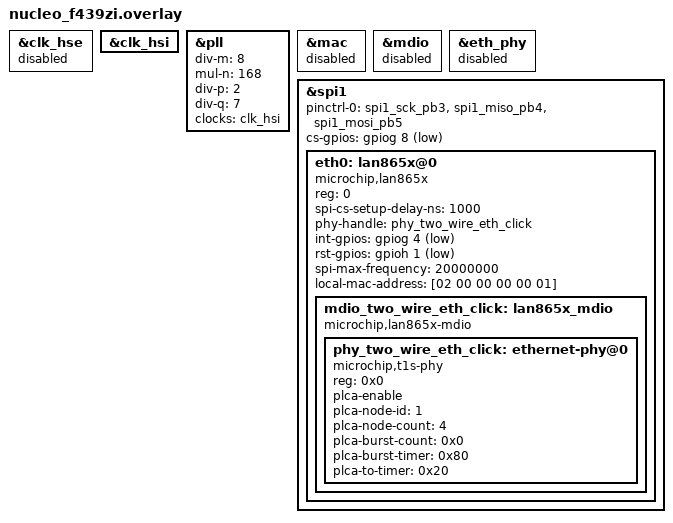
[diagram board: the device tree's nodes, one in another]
/*
 * NUCLEO-F439ZI + MikroE Two-Wire ETH Click (LAN8651), wired directly to the
 * ST morpho headers with jumper leads. No Click Shield in between.
 *
 *   click mikroBUS pin        Nucleo morpho      STM32
 *   ------------------------  -----------------  -----
 *   4  SCK                    CN12 pin 31        PB3
 *   5  MISO (SDO)             CN12 pin 27        PB4
 *   6  MOSI (SDI)             CN12 pin 29        PB5
 *   3  CS                     CN12 pin 66        PG8
 *   15 INT (IRQ)              CN12 pin 69        PG4
 *   2  RST                    CN11 pin 31        PH1
 *   7  3.3V                   3V3                -
 *   8  GND                    GND                -
 *
 * This is deliberately the same pinout the MikroE Click Shield for Nucleo-144
 * routes to its socket 3, so moving to the shield later needs no devicetree
 * change - just seat the click in socket 3. click-shield.overlay re-asserts
 * these pins and carries the shield-specific notes. (The shield itself is
 * unproven; see docs/direct-lan8651-stm32f439zi.md.)
 *
 * For the Arduino-header pinout instead, which frees PH1 and keeps the HSE:
 *   west build -b nucleo_f439zi -p always . \
 *       -DEXTRA_DTC_OVERLAY_FILE=arduino-header.overlay
 */

#include <zephyr/dt-bindings/gpio/gpio.h>

/* RST lands on PH1, which is also OSC_OUT. The board default runs the HSE in
 * bypass mode off the ST-LINK's 8 MHz MCO, and on STM32F4 the oscillator block
 * keeps the OSC_OUT pad even in bypass - PH1 then ignores ODR entirely and the
 * LAN8651 never sees its reset pulse. Measured: driving PH1 high still reads
 * back low until the HSE is disabled.
 *
 * Running the PLL from the HSI instead releases PH0/PH1 to the GPIO block.
 * HSI is 16 MHz (vs 8 MHz HSE), so div-m/mul-n change to keep the same 2 MHz
 * PLL input, 336 MHz VCO, 168 MHz SYSCLK and 48 MHz PLL48 as before.
 *
 * COST: HSI is a +/-1% RC oscillator that drifts with temperature, against the
 * HSE's crystal-derived accuracy. For latency measurements that is a real
 * downside - moving the RST lead alone to PF12 (Arduino D8) lets the HSE stay,
 * see arduino-header.overlay.
 */
&clk_hse {
	status = "disabled";
};

&clk_hsi {
	status = "okay";
};

&pll {
	div-m = <8>;
	mul-n = <168>;
	div-p = <2>;
	div-q = <7>;
	clocks = <&clk_hsi>;
	status = "okay";
};

/* The STM32's own MAC/MDIO/PHY would otherwise claim iface 0 and confuse
 * net_if_get_default(). This board has no PHY fitted for it anyway.
 */
&mac {
	status = "disabled";
};

&mdio {
	status = "disabled";
};

&eth_phy {
	status = "disabled";
};

&spi1 {
	status = "okay";
	pinctrl-0 = <&spi1_sck_pb3 &spi1_miso_pb4 &spi1_mosi_pb5>;
	pinctrl-names = "default";

	cs-gpios = <&gpiog 8 GPIO_ACTIVE_LOW>;

	eth0: lan865x@0 {
		compatible = "microchip,lan865x";
		status = "okay";
		reg = <0>;
		spi-cs-setup-delay-ns = <1000>;
		phy-handle = <&phy_two_wire_eth_click>;

		int-gpios = <&gpiog 4 GPIO_ACTIVE_LOW>;
		rst-gpios = <&gpioh 1 GPIO_ACTIVE_LOW>;

		spi-max-frequency = <20000000>;

		/* The LAN8651 has no MAC address in OTP, so without this
		 * net_eth_mac_load() yields 00:00:00:00:00:00, net_if rejects it
		 * ("Invalid MAC address for iface") and the interface stays down.
		 *
		 * Locally-administered address (bit 1 of the first octet set, bit 0
		 * clear). Last octet matches plca-node-id so nodes stay easy to tell
		 * apart in captures - give every other node on the bus its own.
		 */
		local-mac-address = [02 00 00 00 00 01];

		mdio_two_wire_eth_click: lan865x_mdio {
			compatible = "microchip,lan865x-mdio";
			status = "okay";
			#address-cells = <1>;
			#size-cells = <0>;

			phy_two_wire_eth_click: ethernet-phy@0 {
				compatible = "microchip,t1s-phy";
				reg = <0x0>;
				status = "okay";

				plca-enable;
				plca-node-id = <1>;
				plca-node-count = <4>;
				plca-burst-count = <0x0>;
				plca-burst-timer = <0x80>;
				plca-to-timer = <0x20>;
			};
		};
	};
};
